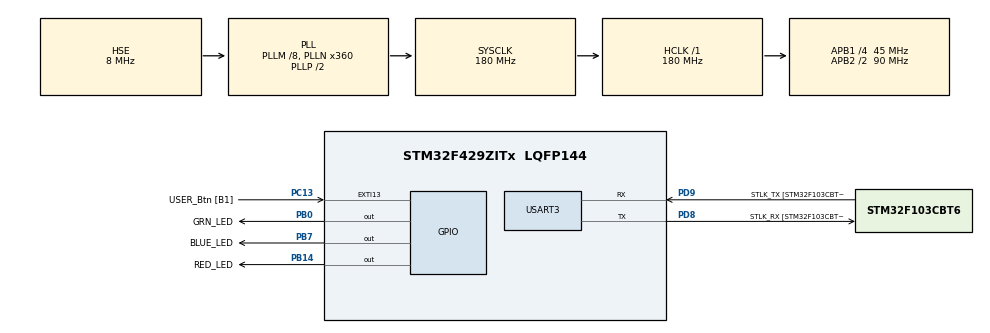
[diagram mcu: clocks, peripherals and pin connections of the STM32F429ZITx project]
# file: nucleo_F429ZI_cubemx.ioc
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Dma.Request0=USART3_TX
Dma.USART3_TX.0.Direction=DMA_MEMORY_TO_PERIPH
Dma.USART3_TX.0.FIFOMode=DMA_FIFOMODE_ENABLE
Dma.USART3_TX.0.FIFOThreshold=DMA_FIFO_THRESHOLD_FULL
Dma.USART3_TX.0.Instance=DMA1_Stream3
Dma.USART3_TX.0.MemBurst=DMA_MBURST_SINGLE
Dma.USART3_TX.0.MemDataAlignment=DMA_MDATAALIGN_BYTE
Dma.USART3_TX.0.MemInc=DMA_MINC_ENABLE
Dma.USART3_TX.0.Mode=DMA_NORMAL
Dma.USART3_TX.0.PeriphBurst=DMA_PBURST_SINGLE
Dma.USART3_TX.0.PeriphDataAlignment=DMA_PDATAALIGN_BYTE
Dma.USART3_TX.0.PeriphInc=DMA_PINC_DISABLE
Dma.USART3_TX.0.Priority=DMA_PRIORITY_MEDIUM
Mcu.Family=STM32F4
Mcu.Name=STM32F429ZITx
Mcu.Package=LQFP144
NVIC.DMA1_Stream3_IRQn=true\:1\:0\:true\:true\:true\:1\:false
NVIC.PriorityGroup=NVIC_PRIORITYGROUP_4
NVIC.USART3_IRQn=true\:1\:0\:true\:true\:true\:2\:true
PA13.GPIO_Label=TMS
PA13.Mode=Serial_Wire
PA13.Signal=SYS_JTMS-SWDIO
PA14.GPIO_Label=TCK
PA14.Mode=Serial_Wire
PA14.Signal=SYS_JTCK-SWCLK
PB0.GPIO_Label=GRN_LED
PB0.Signal=GPIO_Output
PB14.GPIO_Label=RED_LED
PB14.Signal=GPIO_Output
PB7.GPIO_Label=BLUE_LED
PB7.Signal=GPIO_Output
PC13.GPIO_Label=USER_Btn [B1]
PC13.GPIO_ModeDefaultEXTI=GPIO_MODE_EVT_RISING
PC13.Signal=GPXTI13
PC14/OSC32_IN.Mode=LSE-External-Oscillator
PC14/OSC32_IN.Signal=RCC_OSC32_IN
PC15/OSC32_OUT.Mode=LSE-External-Oscillator
PC15/OSC32_OUT.Signal=RCC_OSC32_OUT
PD8.GPIO_Label=STLK_RX [STM32F103CBT6_PA3]
PD8.Mode=Asynchronous
PD8.Signal=USART3_TX
PD9.GPIO_Label=STLK_TX [STM32F103CBT6_PA2]
PD9.Mode=Asynchronous
PD9.Signal=USART3_RX
PH0/OSC_IN.GPIO_Label=MCO [STM32F103CBT6_PA8]
PH0/OSC_IN.Mode=HSE-External-Clock-Source
PH0/OSC_IN.Signal=RCC_OSC_IN
PH1/OSC_OUT.Mode=HSE-External-Clock-Source
PH1/OSC_OUT.Signal=RCC_OSC_OUT
ProjectManager.HeapSize=0x200
ProjectManager.StackSize=0x400
ProjectManager.TargetToolchain=SW4STM32
RCC.48MHZClocksFreq_Value=51428571.428571425
RCC.AHBFreq_Value=180000000
RCC.APB1CLKDivider=RCC_HCLK_DIV4
RCC.APB1Freq_Value=45000000
RCC.APB1TimFreq_Value=90000000
RCC.APB2CLKDivider=RCC_HCLK_DIV2
RCC.APB2Freq_Value=90000000
RCC.APB2TimCLKDivider=1
RCC.APB2TimFreq_Value=90000000
RCC.CortexFreq_Value=180000000
RCC.HCLKFreq_Value=180000000
RCC.HSE_VALUE=8000000
RCC.HSI_VALUE=16000000
RCC.PLLM=8
RCC.PLLMUL=RCC_PLL_MUL9
RCC.PLLN=360
RCC.PLLQ=7
RCC.PLLSourceVirtual=RCC_PLLSOURCE_HSE
RCC.PRESCALERUSB=RCC_USBCLKSOURCE_PLL_DIV1_5
RCC.SYSCLKFreq_VALUE=180000000
RCC.SYSCLKSource=RCC_SYSCLKSOURCE_PLLCLK
RCC.SYSCLKSourceVirtual=RCC_SYSCLKSOURCE_PLLCLK
RCC.USBFreq_Value=48000000
RCC.VCOOutputFreq_Value=360000000
USART3.VirtualMode=VM_ASYNC
board=NUCLEO-F429ZI

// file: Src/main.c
/**
  ******************************************************************************
  * @file           : main.c
  * @brief          : Main program body
  ******************************************************************************
  ** This notice applies to any and all portions of this file
  * that are not between comment pairs USER CODE BEGIN and
  * USER CODE END. Other portions of this file, whether
  * inserted by the user or by software development tools
  * are owned by their respective copyright owners.
  *
  * COPYRIGHT(c) 2018 STMicroelectronics
  *
  * Redistribution and use in source and binary forms, with or without modification,
  * are permitted provided that the following conditions are met:
  *   1. Redistributions of source code must retain the above copyright notice,
  *      this list of conditions and the following disclaimer.
  *   2. Redistributions in binary form must reproduce the above copyright notice,
  *      this list of conditions and the following disclaimer in the documentation
  *      and/or other materials provided with the distribution.
  *   3. Neither the name of STMicroelectronics nor the names of its contributors
  *      may be used to endorse or promote products derived from this software
  *      without specific prior written permission.
  *
  * THIS SOFTWARE IS PROVIDED BY THE COPYRIGHT HOLDERS AND CONTRIBUTORS "AS IS"
  * AND ANY EXPRESS OR IMPLIED WARRANTIES, INCLUDING, BUT NOT LIMITED TO, THE
  * IMPLIED WARRANTIES OF MERCHANTABILITY AND FITNESS FOR A PARTICULAR PURPOSE ARE
  * DISCLAIMED. IN NO EVENT SHALL THE COPYRIGHT HOLDER OR CONTRIBUTORS BE LIABLE
  * FOR ANY DIRECT, INDIRECT, INCIDENTAL, SPECIAL, EXEMPLARY, OR CONSEQUENTIAL
  * DAMAGES (INCLUDING, BUT NOT LIMITED TO, PROCUREMENT OF SUBSTITUTE GOODS OR
  * SERVICES; LOSS OF USE, DATA, OR PROFITS; OR BUSINESS INTERRUPTION) HOWEVER
  * CAUSED AND ON ANY THEORY OF LIABILITY, WHETHER IN CONTRACT, STRICT LIABILITY,
  * OR TORT (INCLUDING NEGLIGENCE OR OTHERWISE) ARISING IN ANY WAY OUT OF THE USE
  * OF THIS SOFTWARE, EVEN IF ADVISED OF THE POSSIBILITY OF SUCH DAMAGE.
  *
  ******************************************************************************
  */
#include "main.h"
#include "stm32f4xx_hal.h"

/* USER CODE BEGIN Includes */
#include "string.h"

/* USER CODE END Includes */

UART_HandleTypeDef huart3;
DMA_HandleTypeDef hdma_usart3_tx;

/* USER CODE BEGIN PV */
/* Private variables ---------------------------------------------------------*/
//static HAL_StatusTypeDef status;
static int counter = 0;
static char uart_buffer[40];
static volatile int dma_complete = 0;

/* USER CODE END PV */

void SystemClock_Config(void);
static void MX_GPIO_Init(void);
static void MX_DMA_Init(void);
static void MX_USART3_UART_Init(void);
static void MX_NVIC_Init(void);

/* USER CODE BEGIN PFP */
/* Private function prototypes -----------------------------------------------*/

/* USER CODE END PFP */

int main(void)
{

  /* MCU Configuration----------------------------------------------------------*/

  /* Reset of all peripherals, Initializes the Flash interface and the Systick. */
  HAL_Init();

  /* Configure the system clock */
  SystemClock_Config();

  /* Initialize all configured peripherals */
  MX_GPIO_Init();
  MX_DMA_Init();
  MX_USART3_UART_Init();

  /* Initialize interrupts */
  MX_NVIC_Init();
  /* USER CODE BEGIN 2 */

  HAL_GPIO_WritePin(GPIOB, GRN_LED_Pin, GPIO_PIN_SET);
  HAL_UART_Transmit( &huart3, (uint8_t *) &"Booted.\r\n", 9, 1000);

  /* USER CODE END 2 */

  /* Infinite loop */
  /* USER CODE BEGIN WHILE */

  dma_complete = 1;
  while (1)
  {
	  if (dma_complete == 1)
	  {
		  dma_complete = 0;
		  counter++;
		  sprintf( uart_buffer, "count: %d\r\n", counter );
		  HAL_UART_Transmit_DMA( &huart3, (uint8_t*) uart_buffer, strlen(uart_buffer) );
	  }

  /* USER CODE END WHILE */

  }

}

void SystemClock_Config(void)
{

  RCC_OscInitTypeDef RCC_OscInitStruct;
  RCC_ClkInitTypeDef RCC_ClkInitStruct;

    /**Configure the main internal regulator output voltage
    */
  __HAL_RCC_PWR_CLK_ENABLE();

  __HAL_PWR_VOLTAGESCALING_CONFIG(PWR_REGULATOR_VOLTAGE_SCALE1);

    /**Initializes the CPU, AHB and APB busses clocks
    */
  RCC_OscInitStruct.OscillatorType = RCC_OSCILLATORTYPE_HSE;
  RCC_OscInitStruct.HSEState = RCC_HSE_BYPASS;
  RCC_OscInitStruct.PLL.PLLState = RCC_PLL_ON;
  RCC_OscInitStruct.PLL.PLLSource = RCC_PLLSOURCE_HSE;
  RCC_OscInitStruct.PLL.PLLM = 8;
  RCC_OscInitStruct.PLL.PLLN = 360;
  RCC_OscInitStruct.PLL.PLLP = RCC_PLLP_DIV2;
  RCC_OscInitStruct.PLL.PLLQ = 7;
  if (HAL_RCC_OscConfig(&RCC_OscInitStruct) != HAL_OK)
  {
    _Error_Handler(__FILE__, __LINE__);
  }

    /**Activate the Over-Drive mode
    */
  if (HAL_PWREx_EnableOverDrive() != HAL_OK)
  {
    _Error_Handler(__FILE__, __LINE__);
  }

    /**Initializes the CPU, AHB and APB busses clocks
    */
  RCC_ClkInitStruct.ClockType = RCC_CLOCKTYPE_HCLK|RCC_CLOCKTYPE_SYSCLK
                              |RCC_CLOCKTYPE_PCLK1|RCC_CLOCKTYPE_PCLK2;
  RCC_ClkInitStruct.SYSCLKSource = RCC_SYSCLKSOURCE_PLLCLK;
  RCC_ClkInitStruct.AHBCLKDivider = RCC_SYSCLK_DIV1;
  RCC_ClkInitStruct.APB1CLKDivider = RCC_HCLK_DIV4;
  RCC_ClkInitStruct.APB2CLKDivider = RCC_HCLK_DIV2;

  if (HAL_RCC_ClockConfig(&RCC_ClkInitStruct, FLASH_LATENCY_5) != HAL_OK)
  {
    _Error_Handler(__FILE__, __LINE__);
  }

    /**Configure the Systick interrupt time
    */
  HAL_SYSTICK_Config(HAL_RCC_GetHCLKFreq()/1000);

    /**Configure the Systick
    */
  HAL_SYSTICK_CLKSourceConfig(SYSTICK_CLKSOURCE_HCLK);

  /* SysTick_IRQn interrupt configuration */
  HAL_NVIC_SetPriority(SysTick_IRQn, 0, 0);
}

/**
  * @brief NVIC Configuration.
  * @retval None
  */
static void MX_NVIC_Init(void)
{
  /* DMA1_Stream3_IRQn interrupt configuration */
  HAL_NVIC_SetPriority(DMA1_Stream3_IRQn, 1, 0);
  HAL_NVIC_EnableIRQ(DMA1_Stream3_IRQn);
  /* USART3_IRQn interrupt configuration */
  HAL_NVIC_SetPriority(USART3_IRQn, 1, 0);
  HAL_NVIC_EnableIRQ(USART3_IRQn);
}

/* USART3 init function */
static void MX_USART3_UART_Init(void)
{

  huart3.Instance = USART3;
  huart3.Init.BaudRate = 115200;
  huart3.Init.WordLength = UART_WORDLENGTH_8B;
  huart3.Init.StopBits = UART_STOPBITS_1;
  huart3.Init.Parity = UART_PARITY_NONE;
  huart3.Init.Mode = UART_MODE_TX_RX;
  huart3.Init.HwFlowCtl = UART_HWCONTROL_NONE;
  huart3.Init.OverSampling = UART_OVERSAMPLING_16;
  if (HAL_UART_Init(&huart3) != HAL_OK)
  {
    _Error_Handler(__FILE__, __LINE__);
  }

}

static void MX_DMA_Init(void)
{
  /* DMA controller clock enable */
  __HAL_RCC_DMA1_CLK_ENABLE();

}

/** Configure pins as
        * Analog
        * Input
        * Output
        * EVENT_OUT
        * EXTI
*/
static void MX_GPIO_Init(void)
{

  GPIO_InitTypeDef GPIO_InitStruct;

  /* GPIO Ports Clock Enable */
  __HAL_RCC_GPIOC_CLK_ENABLE();
  __HAL_RCC_GPIOH_CLK_ENABLE();
  __HAL_RCC_GPIOB_CLK_ENABLE();
  __HAL_RCC_GPIOD_CLK_ENABLE();
  __HAL_RCC_GPIOA_CLK_ENABLE();

  /*Configure GPIO pin Output Level */
  HAL_GPIO_WritePin(GPIOB, GRN_LED_Pin|RED_LED_Pin|BLUE_LED_Pin, GPIO_PIN_RESET);

  /*Configure GPIO pin : USER_Btn_Pin */
  GPIO_InitStruct.Pin = USER_Btn_Pin;
  GPIO_InitStruct.Mode = GPIO_MODE_EVT_RISING;
  GPIO_InitStruct.Pull = GPIO_NOPULL;
  HAL_GPIO_Init(USER_Btn_GPIO_Port, &GPIO_InitStruct);

  /*Configure GPIO pins : GRN_LED_Pin RED_LED_Pin BLUE_LED_Pin */
  GPIO_InitStruct.Pin = GRN_LED_Pin|RED_LED_Pin|BLUE_LED_Pin;
  GPIO_InitStruct.Mode = GPIO_MODE_OUTPUT_PP;
  GPIO_InitStruct.Pull = GPIO_NOPULL;
  GPIO_InitStruct.Speed = GPIO_SPEED_FREQ_LOW;
  HAL_GPIO_Init(GPIOB, &GPIO_InitStruct);

}

/* USER CODE BEGIN 4 */

void HAL_UART_TxCpltCallback (UART_HandleTypeDef *huart)
{
	dma_complete = 1;
}

/* USER CODE END 4 */

void _Error_Handler(char *file, int line)
{
  while(1)
  {
  }
}

/************************ (C) COPYRIGHT STMicroelectronics *****END OF FILE****/
